# ATmega169PA device description
Architecture: AVR8; Family: megaAVR
Registers are 8-bit, access not given, no defined reset value unless marked. A register's access mark holds for its fields unless they carry their own. Offsets are from the block's base; [hi:lo] are bit positions.

## TC2 (TC8_ASYNC module) — Timer/Counter, 8-bit Async
Instances: TC2 0x00
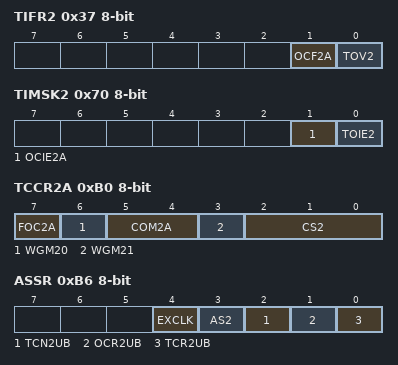
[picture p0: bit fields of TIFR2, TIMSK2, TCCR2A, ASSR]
0x37 TIFR2 — Timer/Counter2 Interrupt Flag Register
  [1] OCF2A — Timer/Counter2 Output Compare Flag 2
  [0] TOV2 — Timer/Counter2 Overflow Flag
0x43 GTCCR — General Timer/Counter Control Register
  [1] PSR2 — Prescaler Reset Timer/Counter2
0x70 TIMSK2 — Timer/Counter2 Interrupt Mask register
  [1] OCIE2A — Timer/Counter2 Output Compare Match Interrupt Enable
  [0] TOIE2 — Timer/Counter2 Overflow Interrupt Enable
0xB0 TCCR2A — Timer/Counter2 Control Register
  [7] FOC2A — Force Output Compare A
  [6] WGM20 — Waveform Generation Mode
    0=Normal; 2=PWM, Phase Correct; 1=CTC; 3=Fast PWM
  [5:4] COM2A — Compare Output Mode bits
  [3] WGM21 — Waveform Generation Mode
  [2:0] CS2 — Clock Select bits
    0=No Clock Source (Stopped); 1=Running, No Prescaling; 2=Running, CLK/8; 3=Running, CLK/32; 4=Running, CLK/64; 5=Running, CLK/128; 6=Running, CLK/256; 7=Running, CLK/1024
0xB2 TCNT2 — Timer/Counter2
  [7:0] TCNT2 — Timer/Counter2 bits
0xB3 OCR2A — Timer/Counter2 Output Compare Register
  [7:0] OCR2A — Timer/Counter2 Output Compare A
0xB6 ASSR — Asynchronous Status Register
  [4] EXCLK — Enable External Clock Interrupt
  [3] AS2 — AS2: Asynchronous Timer/Counter2
  [2] TCN2UB — TCN2UB: Timer/Counter2 Update Busy
  [1] OCR2UB — Output Compare Register2 Update Busy
  [0] TCR2UB — TCR2UB: Timer/Counter Control Register2 Update Busy

## WDT — Watchdog Timer
Instances: WDT 0x00
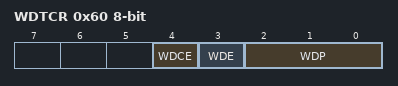
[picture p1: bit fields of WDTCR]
0x60 WDTCR — Watchdog Timer Control Register
  [4] WDCE — Watchdog Change Enable
  [3] WDE — Watch Dog Enable
  [2:0] WDP — Watch Dog Timer Prescaler bits
    0=Oscillator Cycles 16K; 1=Oscillator Cycles 32K; 2=Oscillator Cycles 64K; 3=Oscillator Cycles 128K; 4=Oscillator Cycles 256K; 5=Oscillator Cycles 512K; 6=Oscillator Cycles 1024K; 7=Oscillator Cycles 2048K

## EEPROM
Instances: EEPROM 0x00
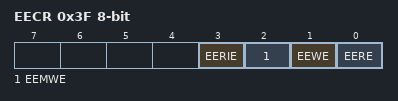
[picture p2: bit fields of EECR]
0x3F EECR — EEPROM Control Register
  [3] EERIE — EEPROM Ready Interrupt Enable
  [2] EEMWE — EEPROM Master Write Enable
  [1] EEWE — EEPROM Write Enable
  [0] EERE — EEPROM Read Enable
0x40 EEDR — EEPROM Data Register
  [7:0] EEDR — EEPROM Data Bits
0x41 EEAR 16-bit — EEPROM Address Register Bytes
  [8:0] EEAR — EEPROM Address Bits

## SPI — Serial Peripheral Interface
Instances: SPI 0x00
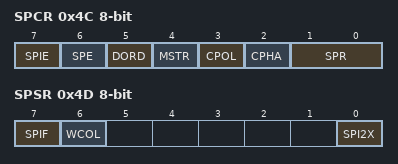
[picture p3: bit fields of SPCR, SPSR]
0x4C SPCR — SPI Control Register
  [7] SPIE — SPI Interrupt Enable
  [6] SPE — SPI Enable
  [5] DORD — Data Order
  [4] MSTR — Master/Slave Select
  [3] CPOL — Clock polarity
  [2] CPHA — Clock Phase
  [1:0] SPR — SPI Clock Rate Selects
    0=fosc/4; 1=fosc/16; 2=fosc/64; 3=fosc/128; 4=fosc/2; 5=fosc/8; 6=fosc/32; 7=fosc/64
0x4D SPSR — SPI Status Register
  [7] SPIF — SPI Interrupt Flag
  [6] WCOL — Write Collision Flag
  [0] SPI2X — Double SPI Speed Bit
0x4E SPDR — SPI Data Register
  [7:0] SPDR — SPI Data bits

## PORTA — I/O Port
Instances: PORTA 0x00
0x20 PINA — Port A Input Pins
0x21 DDRA — Port A Data Direction Register
0x22 PORTA — Port A Data Register

## PORTB — I/O Port
Instances: PORTB 0x00
0x23 PINB — Port B Input Pins
0x24 DDRB — Port B Data Direction Register
0x25 PORTB — Port B Data Register

## PORTC — I/O Port
Instances: PORTC 0x00
0x26 PINC — Port C Input Pins
0x27 DDRC — Port C Data Direction Register
0x28 PORTC — Port C Data Register

## PORTD — I/O Port
Instances: PORTD 0x00
0x29 PIND — Port D Input Pins
0x2A DDRD — Port D Data Direction Register
0x2B PORTD — Port D Data Register

## PORTE — I/O Port
Instances: PORTE 0x00
0x2C PINE — Input Pins, Port E
0x2D DDRE — Data Direction Register, Port E
0x2E PORTE — Data Register, Port E
